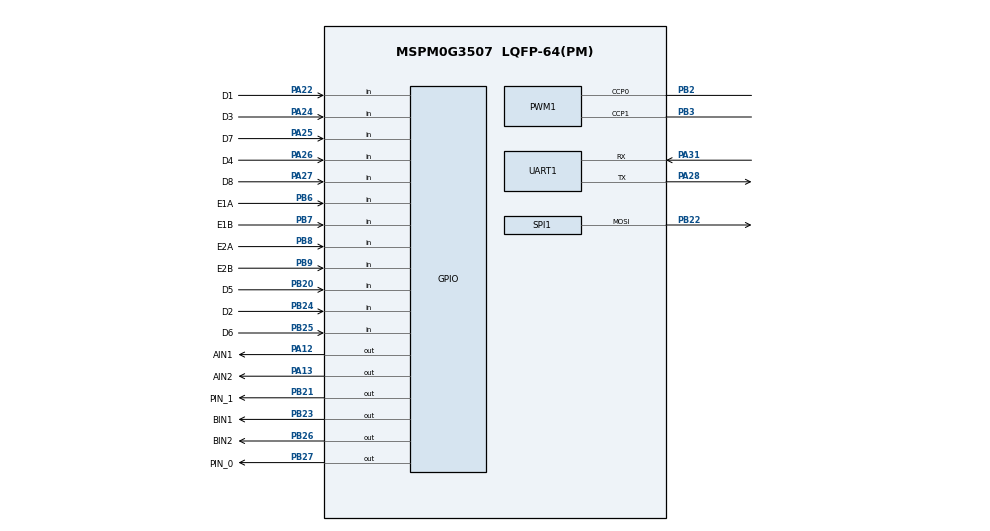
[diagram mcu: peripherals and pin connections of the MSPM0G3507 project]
/**
 * These arguments were used when this file was generated. They will be automatically applied on subsequent loads
 * via the GUI or CLI. Run CLI with '--help' for additional information on how to override these arguments.
 * @cliArgs --device "MSPM0G350X" --part "Default" --package "LQFP-64(PM)" --product "mspm0_sdk@2.10.00.04"
 * @v2CliArgs --device "MSPM0G3507" --package "LQFP-64(PM)" --product "mspm0_sdk@2.10.00.04"
 * @versions {"tool":"1.26.2+4477"}
 */

/**
 * Import the modules used in this configuration.
 */
const GPIO   = scripting.addModule("/ti/driverlib/GPIO", {}, false);
const GPIO1  = GPIO.addInstance();
const GPIO2  = GPIO.addInstance();
const GPIO3  = GPIO.addInstance();
const GPIO4  = GPIO.addInstance();
const GPIO5  = GPIO.addInstance();
const GPIO6  = GPIO.addInstance();
const GPIO7  = GPIO.addInstance();
const PWM    = scripting.addModule("/ti/driverlib/PWM", {}, false);
const PWM1   = PWM.addInstance();
const SPI    = scripting.addModule("/ti/driverlib/SPI", {}, false);
const SPI1   = SPI.addInstance();
const SYSCTL = scripting.addModule("/ti/driverlib/SYSCTL");
const TIMER  = scripting.addModule("/ti/driverlib/TIMER", {}, false);
const TIMER1 = TIMER.addInstance();
const UART   = scripting.addModule("/ti/driverlib/UART", {}, false);
const UART1  = UART.addInstance();

/**
 * Write custom configuration values to the imported modules.
 */
const divider9       = system.clockTree["UDIV"];
divider9.divideValue = 2;

const multiplier2         = system.clockTree["PLL_QDIV"];
multiplier2.multiplyValue = 4;

const mux4       = system.clockTree["EXHFMUX"];
mux4.inputSelect = "EXHFMUX_XTAL";

const mux8       = system.clockTree["HSCLKMUX"];
mux8.inputSelect = "HSCLKMUX_SYSPLL0";

const mux12       = system.clockTree["SYSPLLMUX"];
mux12.inputSelect = "zSYSPLLMUX_HFCLK";

const pinFunction4       = system.clockTree["HFXT"];
pinFunction4.inputFreq   = 40;
pinFunction4.enable      = true;
pinFunction4.HFXTStartup = 100;

GPIO1.$name                         = "Chassis_MotorA";
GPIO1.associatedPins.create(2);
GPIO1.associatedPins[0].$name       = "AIN1";
GPIO1.associatedPins[0].pin.$assign = "PA12";
GPIO1.associatedPins[1].$name       = "AIN2";
GPIO1.associatedPins[1].pin.$assign = "PA13";

const Board = scripting.addModule("/ti/driverlib/Board", {}, false);

GPIO2.$name                         = "Chassis_MotorB";
GPIO2.associatedPins.create(2);
GPIO2.associatedPins[0].$name       = "BIN1";
GPIO2.associatedPins[0].pin.$assign = "PB23";
GPIO2.associatedPins[1].$name       = "BIN2";
GPIO2.associatedPins[1].pin.$assign = "PB26";

GPIO3.$name                         = "led";
GPIO3.associatedPins[0].$name       = "PIN_0";
GPIO3.associatedPins[0].pin.$assign = "PB27";

GPIO4.$name                              = "Digital";
GPIO4.associatedPins.create(8);
GPIO4.associatedPins[0].$name            = "D1";
GPIO4.associatedPins[0].direction        = "INPUT";
GPIO4.associatedPins[0].internalResistor = "PULL_UP";
GPIO4.associatedPins[0].pin.$assign      = "PA22";
GPIO4.associatedPins[1].$name            = "D2";
GPIO4.associatedPins[1].direction        = "INPUT";
GPIO4.associatedPins[1].internalResistor = "PULL_UP";
GPIO4.associatedPins[1].pin.$assign      = "PB24";
GPIO4.associatedPins[2].$name            = "D3";
GPIO4.associatedPins[2].direction        = "INPUT";
GPIO4.associatedPins[2].internalResistor = "PULL_UP";
GPIO4.associatedPins[2].pin.$assign      = "PA24";
GPIO4.associatedPins[3].$name            = "D4";
GPIO4.associatedPins[3].direction        = "INPUT";
GPIO4.associatedPins[3].internalResistor = "PULL_UP";
GPIO4.associatedPins[3].pin.$assign      = "PA26";
GPIO4.associatedPins[4].$name            = "D5";
GPIO4.associatedPins[4].direction        = "INPUT";
GPIO4.associatedPins[4].internalResistor = "PULL_UP";
GPIO4.associatedPins[4].pin.$assign      = "PB20";
GPIO4.associatedPins[5].$name            = "D6";
GPIO4.associatedPins[5].direction        = "INPUT";
GPIO4.associatedPins[5].internalResistor = "PULL_UP";
GPIO4.associatedPins[5].pin.$assign      = "PB25";
GPIO4.associatedPins[6].$name            = "D7";
GPIO4.associatedPins[6].direction        = "INPUT";
GPIO4.associatedPins[6].internalResistor = "PULL_UP";
GPIO4.associatedPins[6].pin.$assign      = "PA25";
GPIO4.associatedPins[7].$name            = "D8";
GPIO4.associatedPins[7].direction        = "INPUT";
GPIO4.associatedPins[7].internalResistor = "PULL_UP";
GPIO4.associatedPins[7].pin.$assign      = "PA27";

GPIO5.$name                              = "EncoderA";
GPIO5.associatedPins.create(2);
GPIO5.associatedPins[0].$name            = "E1A";
GPIO5.associatedPins[0].direction        = "INPUT";
GPIO5.associatedPins[0].internalResistor = "PULL_UP";
GPIO5.associatedPins[0].interruptEn      = true;
GPIO5.associatedPins[0].polarity         = "RISE_FALL";
GPIO5.associatedPins[0].pin.$assign      = "PB6";
GPIO5.associatedPins[1].$name            = "E1B";
GPIO5.associatedPins[1].direction        = "INPUT";
GPIO5.associatedPins[1].internalResistor = "PULL_UP";
GPIO5.associatedPins[1].pin.$assign      = "PB7";

GPIO6.$name                              = "EncoderB";
GPIO6.associatedPins.create(2);
GPIO6.associatedPins[0].direction        = "INPUT";
GPIO6.associatedPins[0].internalResistor = "PULL_UP";
GPIO6.associatedPins[0].interruptEn      = true;
GPIO6.associatedPins[0].polarity         = "RISE_FALL";
GPIO6.associatedPins[0].$name            = "E2A";
GPIO6.associatedPins[0].pin.$assign      = "PB8";
GPIO6.associatedPins[1].direction        = "INPUT";
GPIO6.associatedPins[1].internalResistor = "PULL_UP";
GPIO6.associatedPins[1].$name            = "E2B";
GPIO6.associatedPins[1].pin.$assign      = "PB9";

GPIO7.$name                          = "ICM20602";
GPIO7.associatedPins[0].$name        = "PIN_1";
GPIO7.associatedPins[0].initialValue = "SET";
GPIO7.associatedPins[0].pin.$assign  = "PB21";

PWM1.$name                              = "Chassis_Motor_PWM";
PWM1.timerCount                         = 2500;
PWM1.pwmMode                            = "EDGE_ALIGN_UP";
PWM1.timerStartTimer                    = true;
PWM1.peripheral.ccp0Pin.$assign         = "PB2";
PWM1.peripheral.ccp1Pin.$assign         = "PB3";
PWM1.PWM_CHANNEL_0.$name                = "ti_driverlib_pwm_PWMTimerCC0";
PWM1.PWM_CHANNEL_1.$name                = "ti_driverlib_pwm_PWMTimerCC1";
PWM1.ccp0PinConfig.direction            = scripting.forceWrite("OUTPUT");
PWM1.ccp0PinConfig.hideOutputInversion  = scripting.forceWrite(false);
PWM1.ccp0PinConfig.onlyInternalResistor = scripting.forceWrite(false);
PWM1.ccp0PinConfig.passedPeripheralType = scripting.forceWrite("Digital");
PWM1.ccp0PinConfig.$name                = "ti_driverlib_gpio_GPIOPinGeneric2";
PWM1.ccp1PinConfig.direction            = scripting.forceWrite("OUTPUT");
PWM1.ccp1PinConfig.hideOutputInversion  = scripting.forceWrite(false);
PWM1.ccp1PinConfig.onlyInternalResistor = scripting.forceWrite(false);
PWM1.ccp1PinConfig.passedPeripheralType = scripting.forceWrite("Digital");
PWM1.ccp1PinConfig.$name                = "ti_driverlib_gpio_GPIOPinGeneric3";

SPI1.$name                              = "SPI_ICM20602";
SPI1.frameFormat                        = "MOTO3";
SPI1.polarity                           = "1";
SPI1.targetBitRate                      = 1000000;
SPI1.sclkPinConfig.direction            = scripting.forceWrite("OUTPUT");
SPI1.sclkPinConfig.onlyInternalResistor = scripting.forceWrite(false);
SPI1.sclkPinConfig.passedPeripheralType = scripting.forceWrite("Digital");
SPI1.sclkPinConfig.$name                = "ti_driverlib_gpio_GPIOPinGeneric4";
SPI1.mosiPinConfig.direction            = scripting.forceWrite("OUTPUT");
SPI1.mosiPinConfig.hideOutputInversion  = scripting.forceWrite(false);
SPI1.mosiPinConfig.onlyInternalResistor = scripting.forceWrite(false);
SPI1.mosiPinConfig.passedPeripheralType = scripting.forceWrite("Digital");
SPI1.mosiPinConfig.$name                = "ti_driverlib_gpio_GPIOPinGeneric5";
SPI1.misoPinConfig.onlyInternalResistor = scripting.forceWrite(false);
SPI1.misoPinConfig.passedPeripheralType = scripting.forceWrite("Digital");
SPI1.misoPinConfig.$name                = "ti_driverlib_gpio_GPIOPinGeneric6";
SPI1.peripheral.$assign                 = "SPI1";
SPI1.peripheral.mosiPin.$assign         = "PB22";

SYSCTL.forceDefaultClkConfig = true;
SYSCTL.clockTreeEn           = true;

TIMER1.$name              = "TIMER_Chassis_Motor_Encoder_Read";
TIMER1.timerClkPrescale   = 256;
TIMER1.timerMode          = "PERIODIC";
TIMER1.interrupts         = ["ZERO"];
TIMER1.timerStartTimer    = true;
TIMER1.timerPeriod        = "20 ms";
TIMER1.peripheral.$assign = "TIMG0";

UART1.targetBaudRate                   = 115200;
UART1.$name                            = "UART_BLUETOOTH";
UART1.enabledInterrupts                = ["RX"];
UART1.peripheral.$assign               = "UART0";
UART1.peripheral.rxPin.$assign         = "PA31";
UART1.peripheral.txPin.$assign         = "PA28";
UART1.txPinConfig.direction            = scripting.forceWrite("OUTPUT");
UART1.txPinConfig.hideOutputInversion  = scripting.forceWrite(false);
UART1.txPinConfig.onlyInternalResistor = scripting.forceWrite(false);
UART1.txPinConfig.passedPeripheralType = scripting.forceWrite("Digital");
UART1.txPinConfig.$name                = "ti_driverlib_gpio_GPIOPinGeneric0";
UART1.rxPinConfig.hideOutputInversion  = scripting.forceWrite(false);
UART1.rxPinConfig.onlyInternalResistor = scripting.forceWrite(false);
UART1.rxPinConfig.passedPeripheralType = scripting.forceWrite("Digital");
UART1.rxPinConfig.$name                = "ti_driverlib_gpio_GPIOPinGeneric1";

/**
 * Pinmux solution for unlocked pins/peripherals. This ensures that minor changes to the automatic solver in a future
 * version of the tool will not impact the pinmux you originally saw.  These lines can be completely deleted in order to
 * re-solve from scratch.
 */
pinFunction4.peripheral.$suggestSolution           = "SYSCTL";
pinFunction4.peripheral.hfxInPin.$suggestSolution  = "PA5";
pinFunction4.peripheral.hfxOutPin.$suggestSolution = "PA6";
Board.peripheral.$suggestSolution                  = "DEBUGSS";
Board.peripheral.swclkPin.$suggestSolution         = "PA20";
Board.peripheral.swdioPin.$suggestSolution         = "PA19";
PWM1.peripheral.$suggestSolution                   = "TIMA1";
SPI1.peripheral.sclkPin.$suggestSolution           = "PA17";
SPI1.peripheral.misoPin.$suggestSolution           = "PA16";
